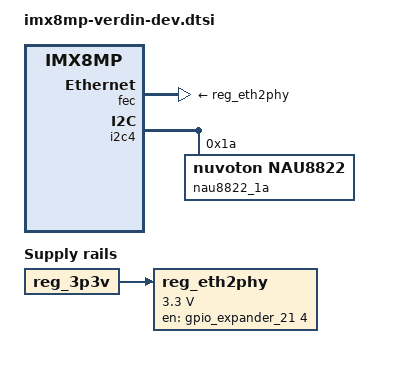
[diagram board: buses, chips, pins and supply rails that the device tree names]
// SPDX-License-Identifier: GPL-2.0+ OR MIT
/*
 * Copyright 2020 Toradex
 */

#include "imx8mp-verdin-dahlia.dtsi"

/ {
	reg_eth2phy: regulator-eth2phy {
		compatible = "regulator-fixed";
		enable-active-high;
		gpio = <&gpio_expander_21 4 GPIO_ACTIVE_HIGH>; /* ETH_PWR_EN */
		off-on-delay = <500000>;
		regulator-max-microvolt = <3300000>;
		regulator-min-microvolt = <3300000>;
		regulator-name = "+V3.3_ETH";
		startup-delay-us = <200000>;
		vin-supply = <&reg_3p3v>;
	};

	sound_card: sound-card {
		compatible = "simple-audio-card";
		simple-audio-card,bitclock-master = <&dailink_master>;
		simple-audio-card,format = "i2s";
		simple-audio-card,frame-master = <&dailink_master>;
		simple-audio-card,name = "imx8mp-nau8822";
		simple-audio-card,routing =
			"Headphones", "LHP",
			"Headphones", "RHP",
			"Speaker", "LSPK",
			"Speaker", "RSPK",
			"Line Out", "AUXOUT1",
			"Line Out", "AUXOUT2",
			"LAUX", "Line In",
			"RAUX", "Line In",
			"LMICP",    "Mic In",
			"RMICP",    "Mic In";
		simple-audio-card,widgets =
			"Headphones", "Headphones",
			"Line Out", "Line Out",
			"Speaker", "Speaker",
			"Microphone", "Mic In",
			"Line", "Line In";

		dailink_master: simple-audio-card,codec {
			sound-dai = <&nau8822_1a>;
			clocks = <&audiomix_clk IMX8MP_CLK_AUDIOMIX_SAI1_MCLK1>;
		};

		simple-audio-card,cpu {
			sound-dai = <&sai1>;
		};
	};
};

&fec {
	phy-supply = <&reg_eth2phy>;
	status = "okay";
};

&gpio_expander_21 {
	status = "okay";
	vcc-supply = <&reg_1p8v>;
};

/* Verdin I2C_1 */
&i2c4 {
	/* Audio Codec */
	nau8822_1a: codec-nau@1a {
		compatible = "nuvoton,nau8822";
		#sound-dai-cells = <0>;
		reg = <0x1a>;
	};
};

/* Limit frequency on dev board due to long traces and bad signal integrity */
&usdhc2 {
	max-frequency = <100000000>;
};

&wm8904_1a {
	status = "disabled";
};
